# WS63 register map
File version: 1.0
CPU: other r0p0, little endian, MPU, FPU, 3 interrupt priority bits
Registers are 32-bit, read-write, reset 0x0 unless marked. A register's access mark holds for its fields unless they carry their own. Offsets are from the block's base; [hi:lo] are bit positions; {n}, {i} and the like mark numbered series.

## TRNG — True Random Number Generator
Base 0x44114000
0x100 TRNG_FIFO_DATA — TRNG FIFO data output register
  [31:0] trng_data ro — Random data (read to get random number)
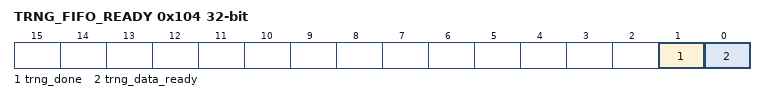
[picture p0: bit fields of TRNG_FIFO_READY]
0x104 TRNG_FIFO_READY — TRNG FIFO ready status
  [1] trng_done ro — TRNG generation done
  [0] trng_data_ready ro — Data ready: 1=data available in FIFO
0x108 TRNG_DATA_ST — TRNG data status register
  [31:0] data_st ro — Data status
0x174 TRNG_FRO_SAMPLE_CLK_SEL — TRNG FRO sample clock select
  [0] fro_sample_clk_sel — FRO sample clock select: 0=inner; 1=external
0x178 TRNG_FRO_DIV_CNT — TRNG FRO divider count
  [7:0] fro_div_cnt — FRO divider count (default 0x1b)

## TCXO — TCXO 64-bit free-running counter (v150)
Base 0x440004C0
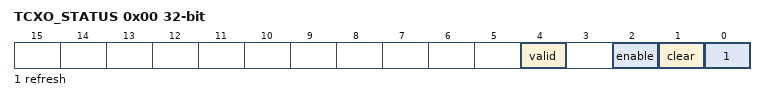
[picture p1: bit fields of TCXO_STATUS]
0x00 TCXO_STATUS — TCXO status and control register
  [4] valid ro — TCXO count value valid flag
  [2] enable — TCXO count enable: 1=enable counting
  [1] clear — TCXO count clear: 1=clear counter
  [0] refresh — TCXO count refresh: 1=trigger count latch
0x04 TCXO_COUNT0 — TCXO counter bits [31:0] in the WS63 two-data-register SDK profile
  [15:0] count0 ro — Legacy accessor for the low 16 bits of counter bits [31:0]; use count0_full for the complete word
  [31:0] count0_full ro — Complete counter value bits [31:0]
0x08 TCXO_COUNT1 — TCXO counter bits [63:32] in the WS63 two-data-register SDK profile
  [15:0] count1 ro — Legacy accessor for the low 16 bits of counter bits [63:32]; use count1_full for the complete word
  [31:0] count1_full ro — Complete counter value bits [63:32]
0x0C TCXO_COUNT2 — Legacy compatibility accessor; not used by the WS63 two-data-register SDK profile, semantics unverified
  [15:0] count2 ro — Legacy field; semantics unverified for the WS63 two-data-register profile
0x10 TCXO_COUNT3 — Legacy compatibility accessor; not used by the WS63 two-data-register SDK profile, semantics unverified
  [15:0] count3 ro — Legacy field; semantics unverified for the WS63 two-data-register profile

## RF_WB_CTL — SYS_CTL2 sub-block: RF Wideband Control Register Block - WL/BT RF analog interface control
Base 0x44004000
0x00 SYS_CTL_ID — System control ID register
0x10 RF_WL_REG_CLK_CTL — RF WL register clock control
0x14 RF_WL_REG_SOFT_RSTN — RF WL register soft reset
0x18 RF_WL_REG_CMD_SOFT_RSTN — RF WL command soft reset
0x1C RF_WL_REG_CMD_FIFO_STS — RF WL command FIFO status
0x20 RF_WL_CBB_DIS — RF WL CBB disable
0x24 RF_BT_CBB_DIS — RF BT CBB disable
0x30 ABB_ADC_CTRL — ABB ADC control
0x34 ABB_DAC_CTRL — ABB DAC control
0x38 ABB_EN_CTRL — ABB enable control
0x3C CFG_WL_ADC_MUX — WL ADC mux configuration
0x40 CFG_RF_MAN_EN_CTRL — RF manual enable control
0x44 CFG_TRXEN_CTRL — TRX enable control
0x48 CFG_DCOC_IQ_CTRL — DCOC IQ control
0x4C CFG_PA_IDX_CTRL — PA index control
0x50 CFG_LPF_CTRL — LPF control
0x54 CFG_RADAR_CTRL — Radar control
0x58 CFG_PPA_CODE — PPA code register
0x5C CFG_TEMP_LOCK_CTRL — Temperature lock control
0x60 CFG_TEMP_BANK_SEL_CTRL — Temperature bank select control
0x64 CFG_RF_DIAG_MUX — RF diagnostic mux

## SHARE_MEM_CTL — SYS_CTL2 sub-block: Shared Memory Control - RAM config, RX/TX DMA descriptor rings for WiFi PHY↔Packet buffer
Base 0x44006C00
0x04 CFG_RAM_CKEN — RAM clock enable
  [23:10] share_ram_cken — Clock enables for the configurable shared RAM banks
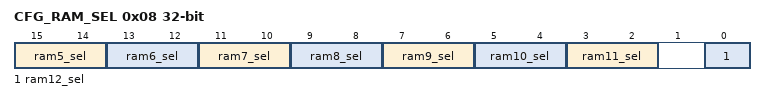
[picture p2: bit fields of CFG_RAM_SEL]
0x08 CFG_RAM_SEL — Share RAM control and RAM select
  [25-2n:24-2n] ram{n}_sel (n=5..11) — RAM{n} selection: 0 packet RAM, 1 BGLE, 2 ITCM, 3 DTCM
  [0] ram12_sel — RAM12 selection: 0 packet RAM, 1 BGLE
0x0C RAM_SW_CONFLICT_CLR — RAM software conflict clear
0x10 RAM_SW_CONFLICT_ST — RAM software conflict status
0x14 RAMX_SW_CONFLICT_BASE_ADDR — RAMX software conflict base address
0x50 CFG_FREQ_BUSDMAC — Bus DMAC frequency configuration
0x58 CFG_RX_EN — RX enable
0x5C CFG_RX_START_ADDR — RX start address
0x60 CFG_RX_END_ADDR — RX end address
0x64 CFG_RX_DONE_STS — RX done status
0x68 CFG_RX_DONE_ADDR — RX done address
0x6C CFG_WLPHY2PKT_RX_RAM_STS — WL PHY-to-packet RX RAM status
0x70 CFG_TX_EN — TX enable
0x74 CFG_TX_START_ADDR — TX start address
0x78 CFG_TX_END_ADDR — TX end address
0x7C CFG_TX_DONE_STS — TX done status
0x80 CFG_TX_DONE_ADDR — TX done address
0x84 CFG_WLPHY2PKT_TX_RAM_STS — WL PHY-to-packet TX RAM status
